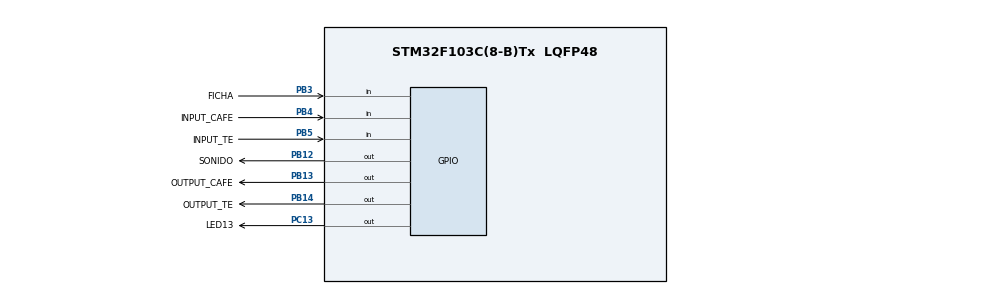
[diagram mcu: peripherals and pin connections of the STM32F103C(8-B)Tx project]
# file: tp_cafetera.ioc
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Mcu.Family=STM32F1
PC15-OSC32_OUT.Mode=LSE-External-Oscillator
PD1-OSC_OUT.Mode=HSE-External-Oscillator
PB14.GPIO_Label=OUTPUT_TE
PC13-TAMPER-RTC.Signal=GPIO_Output
PD0-OSC_IN.Signal=RCC_OSC_IN
PC14-OSC32_IN.Signal=RCC_OSC32_IN
PB13.GPIO_Label=OUTPUT_CAFE
PB13.Signal=GPIO_Output
ProjectManager.StackSize=0x400
PD1-OSC_OUT.Signal=RCC_OSC_OUT
PA13.Signal=SYS_JTMS-SWDIO
PB14.PinState=GPIO_PIN_SET
ProjectManager.TargetToolchain=STM32CubeIDE
PB12.PinState=GPIO_PIN_SET
PB4.GPIO_PuPd=GPIO_PULLUP
PC15-OSC32_OUT.Signal=RCC_OSC32_OUT
PB12.GPIO_Speed=GPIO_SPEED_FREQ_LOW
PD0-OSC_IN.Mode=HSE-External-Oscillator
PB14.Signal=GPIO_Output
board=custom
PC13-TAMPER-RTC.GPIO_Label=LED13
PB12.GPIO_Label=SONIDO
RCC.APB2Freq_Value=8000000
PB3.GPIO_PuPd=GPIO_PULLUP
PB13.PinState=GPIO_PIN_SET
PC13-TAMPER-RTC.PinState=GPIO_PIN_SET
PC14-OSC32_IN.Mode=LSE-External-Oscillator
PB4.GPIO_Label=INPUT_CAFE
PA14.Mode=Serial_Wire
PA13.Mode=Serial_Wire
Mcu.Name=STM32F103C(8-B)Tx
PB3.Signal=GPIO_Input
Mcu.Package=LQFP48
PB5.Signal=GPIO_Input
PB5.GPIO_PuPd=GPIO_PULLUP
PA14.Signal=SYS_JTCK-SWCLK
ProjectManager.HeapSize=0x200
NVIC.PriorityGroup=NVIC_PRIORITYGROUP_4
PB5.GPIO_Label=INPUT_TE
RCC.APB1Freq_Value=8000000
PB12.Signal=GPIO_Output
PB4.Signal=GPIO_Input
PB3.GPIO_Label=FICHA

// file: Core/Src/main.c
/* USER CODE BEGIN Header */
/**
  ******************************************************************************
  * @file           : main.c
  * @brief          : Main program body
  ******************************************************************************
  * @attention
  *
  * <h2><center>&copy; Copyright (c) 2021 STMicroelectronics.
  * All rights reserved.</center></h2>
  *
  * This software component is licensed by ST under BSD 3-Clause license,
  * the "License"; You may not use this file except in compliance with the
  * License. You may obtain a copy of the License at:
  *                        opensource.org/licenses/BSD-3-Clause
  *
  ******************************************************************************
  */
/* USER CODE END Header */
#include "main.h"

/* USER CODE BEGIN Includes */
#include "fsmCafetera.h"
#include "userGpio.h"
/* USER CODE END Includes */

void SystemClock_Config(void);
static void MX_GPIO_Init(void);

/* USER CODE BEGIN 0 */
void HAL_IncTick(void)
{
	cafeteraTick();
}
/* USER CODE END 0 */

int main(void)
{

  /* MCU Configuration--------------------------------------------------------*/

  /* Reset of all peripherals, Initializes the Flash interface and the Systick. */
  HAL_Init();

  /* Configure the system clock */
  SystemClock_Config();

  /* Initialize all configured peripherals */
  MX_GPIO_Init();
  /* USER CODE BEGIN 2 */
  userGpioInit();
  fsmCafeteraInit();
  /* USER CODE END 2 */

  /* Infinite loop */
  /* USER CODE BEGIN WHILE */
  while (1)
  {
	  userGpio();
	  fsmCafetera();

    /* USER CODE END WHILE */

  }
}

void SystemClock_Config(void)
{
  RCC_OscInitTypeDef RCC_OscInitStruct = {0};
  RCC_ClkInitTypeDef RCC_ClkInitStruct = {0};

  /** Initializes the RCC Oscillators according to the specified parameters
  * in the RCC_OscInitTypeDef structure.
  */
  RCC_OscInitStruct.OscillatorType = RCC_OSCILLATORTYPE_HSI;
  RCC_OscInitStruct.HSIState = RCC_HSI_ON;
  RCC_OscInitStruct.HSICalibrationValue = RCC_HSICALIBRATION_DEFAULT;
  RCC_OscInitStruct.PLL.PLLState = RCC_PLL_NONE;
  if (HAL_RCC_OscConfig(&RCC_OscInitStruct) != HAL_OK)
  {
    Error_Handler();
  }
  /** Initializes the CPU, AHB and APB buses clocks
  */
  RCC_ClkInitStruct.ClockType = RCC_CLOCKTYPE_HCLK|RCC_CLOCKTYPE_SYSCLK
                              |RCC_CLOCKTYPE_PCLK1|RCC_CLOCKTYPE_PCLK2;
  RCC_ClkInitStruct.SYSCLKSource = RCC_SYSCLKSOURCE_HSI;
  RCC_ClkInitStruct.AHBCLKDivider = RCC_SYSCLK_DIV1;
  RCC_ClkInitStruct.APB1CLKDivider = RCC_HCLK_DIV1;
  RCC_ClkInitStruct.APB2CLKDivider = RCC_HCLK_DIV1;

  if (HAL_RCC_ClockConfig(&RCC_ClkInitStruct, FLASH_LATENCY_0) != HAL_OK)
  {
    Error_Handler();
  }
}

static void MX_GPIO_Init(void)
{
  GPIO_InitTypeDef GPIO_InitStruct = {0};

  /* GPIO Ports Clock Enable */
  __HAL_RCC_GPIOC_CLK_ENABLE();
  __HAL_RCC_GPIOD_CLK_ENABLE();
  __HAL_RCC_GPIOB_CLK_ENABLE();
  __HAL_RCC_GPIOA_CLK_ENABLE();

  /*Configure GPIO pin Output Level */
  HAL_GPIO_WritePin(LED13_GPIO_Port, LED13_Pin, GPIO_PIN_SET);

  /*Configure GPIO pin Output Level */
  HAL_GPIO_WritePin(GPIOB, SONIDO_Pin|OUTPUT_CAFE_Pin|OUTPUT_TE_Pin, GPIO_PIN_SET);

  /*Configure GPIO pin : LED13_Pin */
  GPIO_InitStruct.Pin = LED13_Pin;
  GPIO_InitStruct.Mode = GPIO_MODE_OUTPUT_PP;
  GPIO_InitStruct.Pull = GPIO_NOPULL;
  GPIO_InitStruct.Speed = GPIO_SPEED_FREQ_LOW;
  HAL_GPIO_Init(LED13_GPIO_Port, &GPIO_InitStruct);

  /*Configure GPIO pins : SONIDO_Pin OUTPUT_CAFE_Pin OUTPUT_TE_Pin */
  GPIO_InitStruct.Pin = SONIDO_Pin|OUTPUT_CAFE_Pin|OUTPUT_TE_Pin;
  GPIO_InitStruct.Mode = GPIO_MODE_OUTPUT_PP;
  GPIO_InitStruct.Pull = GPIO_NOPULL;
  GPIO_InitStruct.Speed = GPIO_SPEED_FREQ_LOW;
  HAL_GPIO_Init(GPIOB, &GPIO_InitStruct);

  /*Configure GPIO pins : FICHA_Pin INPUT_CAFE_Pin INPUT_TE_Pin */
  GPIO_InitStruct.Pin = FICHA_Pin|INPUT_CAFE_Pin|INPUT_TE_Pin;
  GPIO_InitStruct.Mode = GPIO_MODE_INPUT;
  GPIO_InitStruct.Pull = GPIO_PULLUP;
  HAL_GPIO_Init(GPIOB, &GPIO_InitStruct);

}

void Error_Handler(void)
{
  __disable_irq();
  while (1)
  {
  }
}

/************************ (C) COPYRIGHT STMicroelectronics *****END OF FILE****/
